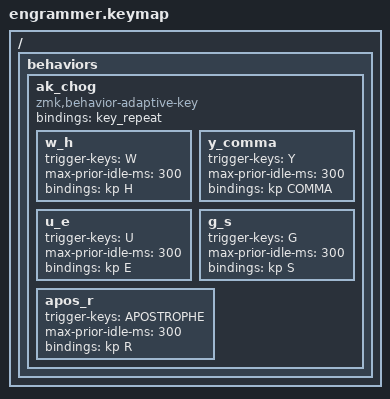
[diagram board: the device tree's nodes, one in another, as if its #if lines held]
#include <behaviors.dtsi>
#include <behaviors/num_word.dtsi> // Requires auto-layer module.
#include <dt-bindings/zmk/keys.h>
#ifdef CONFIG_WIRELESS
  #include <dt-bindings/zmk/bt.h>
  #include <dt-bindings/zmk/outputs.h>
  #define _BT_SEL_KEYS_                                                        \
      &bt BT_SEL 0 &bt BT_SEL 1 &bt BT_SEL 2 &bt BT_SEL 3 &bt BT_CLR
#else
  #define _BT_SEL_KEYS_ &trans &trans &trans &trans &trans
#endif

#include "zmk-helpers/helper.h"
// #include "zmk-helpers/unicode-chars/greek.dtsi"
// #include "zmk-helpers/unicode-chars/german.dtsi"

#define BASE 0
#define NAV  1
#define NUM  2
#define SYS  3

#define XXX &none
#define ___ &trans

#ifndef ZMK_BASE_LAYER
  #define ZMK_BASE_LAYER(name, LT, RT, LM, RM, LB, RB, LH, RH)                 \
      ZMK_LAYER(name, LT RT LM RM LB RB LH RH)
#endif

#include "zmk-helpers/helper.h"
//   q b g . z  v w o y f
//   r n s t m  k * a i h
//   l p d c j  x u ; , '
//                e   

// "rules": {
//   "r": "l",
//   "t": ".",
//   "c": "t",
//   "y": ",",
//   "d": "s",
//   "g": "s",
//   "o": "u",
//   "default": {
//     "type": "repeat"
//   }

#define COMBO_TERM_FAST 18
#define COMBO_TERM_SLOW 30

#define COMBO_IDLE_FAST 150
#define COMBO_IDLE_SLOW 50
#define XXX &none
#define ___ &trans
// ZMK_COMBO(v,   &kp V,           LTR LTM,     DEF, COMBO_TERM_FAST, COMBO_IDLE_FAST)
// ZMK_COMBO(q,   &kp Q,           LBM LBI,     DEF, COMBO_TERM_FAST, COMBO_IDLE_FAST)
// ZMK_COMBO(z,   &kp Z,           LBR LBM,     DEF, COMBO_TERM_FAST, COMBO_IDLE_FAST)
// ZMK_COMBO(qu,  &kp Q &kp U,     LTM LTI,     DEF, COMBO_TERM_FAST, COMBO_IDLE_FAST)

// ZMK_COMBO(p,   &kp P, LMM LMI, DEF, COMBO_TERM_FAST, COMBO_IDLE_FAST)
// ZMK_COMBO(v,   &kp V, LMP LMI, DEF, COMBO_TERM_FAST, COMBO_IDLE_FAST)

 / {
    behaviors {
        ak_chog: ak_chog {
            compatible = "zmk,behavior-adaptive-key";
            #binding-cells = <0>;
            bindings = <&key_repeat>;
            w_h { trigger-keys = <W>; max-prior-idle-ms = <300>; bindings = <&kp H>; };
			y_comma { trigger-keys = <Y>; max-prior-idle-ms = <300>; bindings = <&kp COMMA>; };
			u_e { trigger-keys = <U>; max-prior-idle-ms = <300>; bindings = <&kp E>; };
			g_s { trigger-keys = <G>; max-prior-idle-ms = <300>; bindings = <&kp S>; };
			apos_r { trigger-keys = <APOSTROPHE>; max-prior-idle-ms = <300>; bindings = <&kp R>; };
        };
    };
 };

//    v w d l  ;  '  u o y b 
//    n s t h  .  ,  a e i c 
//    p f m r  /  -  k j x g


ZMK_BASE_LAYER(BASE,
//╭─────────────┬─────────────┬─────────────┬─────────────┬─────────────╮ ╭─────────────┬─────────────┬─────────────┬─────────────┬─────────────╮
    &kp V         &kp W         &kp D         &kp L         &kp SEMI    ,   &kp SQT       &kp U         &kp O         &kp Y         &kp B       ,
//├─────────────┼─────────────┼─────────────┼─────────────┼─────────────┤ ├─────────────┼─────────────┼─────────────┼─────────────┼─────────────┤
    &kp N         &kp S         &kp T         &kp H         &kp DOT     ,   &kp COMMA     &kp A         &kp E         &kp I         &kp C       ,
//├─────────────┼─────────────┼─────────────┼─────────────┼─────────────┤ ├─────────────┼─────────────┼─────────────┼─────────────┼─────────────┤
    &kp P         &kp F         &kp M         &kp R         &kp FSLH    ,   &kp MINUS     &kp K         &kp J         &kp X         &kp G       ,
//╰─────────────┼─────────────┴─────────────┼─────────────┼─────────────┤ ├─────────────┼─────────────┼─────────────┴───────────────────────────╯
                                              &kp BSPC       &ak_chog   ,   &kp SPACE    &kp TAB
//                                          ╰─────────────┴─────────────╯ ╰─────────────┴─────────────╯
)



/* vim: set ft=c tw=146: */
